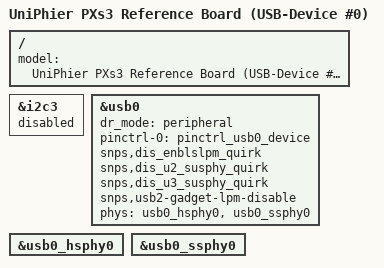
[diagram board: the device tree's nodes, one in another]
/dts-v1/;
#include "uniphier-pxs3-ref.dts"
/ {
	model = "UniPhier PXs3 Reference Board (USB-Device #0)";
};
&i2c3 {
	status = "disabled";
};
&usb0 {
	status = "okay";
	dr_mode = "peripheral";
	pinctrl-0 = <&pinctrl_usb0_device>;
	snps,dis_enblslpm_quirk;
	snps,dis_u2_susphy_quirk;
	snps,dis_u3_susphy_quirk;
	snps,usb2-gadget-lpm-disable;
	phy-names = "usb2-phy", "usb3-phy";
	phys = <&usb0_hsphy0>, <&usb0_ssphy0>;
};
&usb0_hsphy0 {
	/delete-property/ vbus-supply;
};
&usb0_ssphy0 {
	/delete-property/ vbus-supply;
};
/delete-node/ &usb0_hsphy1;
/delete-node/ &usb0_ssphy1;
